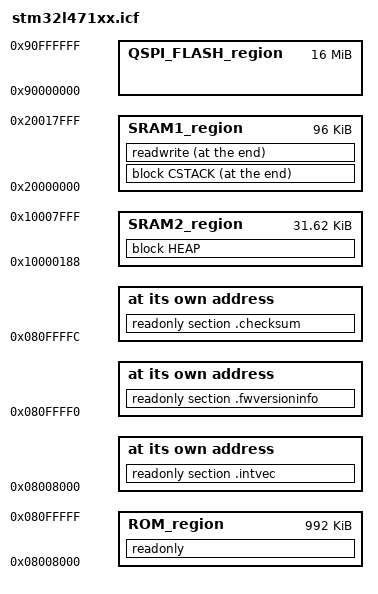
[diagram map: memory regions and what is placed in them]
/* *** IAR (icf)linker file for the firmware inside STM32L471RGT6 and STM32L471VGT6 *** */
//
//    	CSTACK:  4kByte 
//      HEAP:   68kByte 
//		
//
//              
//                     SRAM1 description (96kByte)
//      0x20017FFF      -------------------------       CSTACK start      
//      SRAM1 end       |                   |   |
//                      |       CSTACK      |   |
//                      |       grows       |   |       
//                      |       down        |   |		4kByte (min. 2kByte for Micropython)
//						|                   |   |
//      0x20017000      |                   v   |		CSTACK end
//                      |-----------------------|                
//      0x20016FFF      |                       |      
//                      |                       |
//                      |                       |
//                      |                       |      
//                      |                       |
//                      |                       |		
//                      |                       |
//                      |                       |
//                      |                       |
//                      |                       |
//                      |                       |
//                      |        BSS segment    |		92kkByte 
//                      |                       |
// 						|        Data segment   |
//                      |                       |
// 						|                       |
//                      |                       |
//						|                       |
//                      |                       |
//					 	|                       |
//                      |                       |
//      0x20000000      |-----------------------|         
//      SRAM1 start
//                      
//	
//	
//
//
//                      SRAM2 description (32kByte)
//      0x10007FFF      -------------------------            
//      SRAM2 end       |                   ^  	|                  
//          			|                   |  	|
//                      |                	|   |
//                      |       HEAP        |   |		32kByte-392Byte
//                      |       grows 		|   |		(min. 16kByte for Micropython) 
//                      |       up          |   |
// 						|       			|   |
//                      |       			|   |		
//                      |       			|   |
//                      |       			|   |      	
//                      |       			|   |             
//                      |       			|   |
//                      |       			|   |
//                      |       			|   |
//                		|       			|   |
//		0x10000188		|       			|   |
//                      |-----------------------|
//      0x10000187      |          				|                      
//						|Interrupt Vector Table |	     392Byte reserved to copy IVT
//						|                       |
//      0x10000000    	-------------------------
//      SRAM2 start
//
//
//
//
//                      ROM description (internal flash memory 1MByte)
//      0x080FFFFF      -------------------------            
//      ROM end       	|CRC32, firmware version|                  
//                      |                      	|
//                      |                		|
//                      |                   	|      	
//                      |                  		|
//                      |                      	|
//                      |                      	|
//                      |                      	|
//                      |						|                
//                      |                       | 
//                      |            			|
//                      | mbed +                |		
//                      | Micropython +         |		992kByte-392Byte
//                      | and more      	    |      
//                      |                       |
//                      |                       |
//                      |                       |
//                      |                       |
//                      |                       |
//                      |                       |
//                      |                  	    |       
//                      |                       |
//                      |                       |
//                      |                       |
//                      |                       |
//                      |                       |
//      0x08008188      |                       |
//                      |-----------------------|
//      0x08008187      |                       |  
//                      |Interrupt Vector Table |	     392Byte	
//      0x08008000      |                       |
//                      |---------------------- |
//      0x08007FFF      |CRC32                  |
//                      |						|
//                      |                       |
//                      | Bootloader OpenBlt    |		 32kByte
//                      |                       |
//                      |                       |
//      0x08000000      -------------------------
//      ROM start
//
//
//
//               	  QuadSPI-NOR-Flash description
//                    (MT25QU128ABA with a size of 16MByte)                 			 
//      0x90FFFFFF      -------------------------            
//      QuadSPI end     |						|                  
//                      |                      	|
//                      |                		|
//                      |                   	|      	
//                      |                  		|
//                      |                      	|
//                      |                      	|
//                      |                      	|
//                      |						|                
//                      |                       | 
//                      |            			|
//                      |                       |		
//                      | Flash File System     |
//                      |       			    |      
//                      |                       |
//                      |                       |
//                      |                       |
//                      |                       |
//                      |                       |
//                      |                       |
//                      |                  	    |       
//                      |                       |
//                      |                       |
//                      |                       |
//                      |                       |
//                      |                       |
//                      |                       |
//                      |                       |
//                      |                       |
//                      |						|
//                      |                       |
//                      |                       |	
//                      |                       |
//                      |                       |
//      0x90000000      -------------------------
//      QuadSPI start
//
//
/* **************************************************************** */

/* [ROM = 1024kb = 0x100000] */
/* Interrupt Vector Table */
/* Bootloader space of 32kByte reserved */  
define symbol __intvec_start__     = 0x08008000;

define symbol __region_ROM_start__ = 0x08008000;
define symbol __region_ROM_end__   = 0x080FFFFF;


/* [RAM = 96kb + 32kb = 0x20000] */
/* Vector table dynamic copy: Total: 98 vectors = 392 bytes (0x188) to be reserved in RAM */
define symbol __NVIC_start__          = 0x10000000;
define symbol __NVIC_end__            = 0x10000187; /* Aligned on 8 bytes (392 = 49 x 8) */
define symbol __region_SRAM2_start__  = 0x10000188;
define symbol __region_SRAM2_end__    = 0x10007FFF;
define symbol __region_SRAM1_start__  = 0x20000000;
define symbol __region_SRAM1_end__    = 0x20017FFF;
define symbol __region_RAM_end__      = __region_SRAM1_end__; 
export symbol __region_RAM_end__;	  /* used for micropython gc_collect_root */	

/* [QSPI_FLASH = 16MByte = 0x1000000] */
define symbol __region_QSPI_FLASH_start__    = 0x90000000;
define symbol __region_QSPI_FLASH_end__      = 0x90FFFFFF;


/* Memory regions */
define memory mem with size = 4G;
define region ROM_region = mem:[from __region_ROM_start__ to __region_ROM_end__];
define region SRAM1_region = mem:[from __region_SRAM1_start__ to __region_SRAM1_end__];
define region SRAM2_region = mem:[from __region_SRAM2_start__ to __region_SRAM2_end__];
define region QSPI_FLASH_region = mem:[from __region_QSPI_FLASH_start__ to __region_QSPI_FLASH_end__];


/* Stack and Heap */
/* CSTACK:  4kByte = 0x1000 */
/* HEAP:  32kByte = 0x8000 */
define symbol __size_cstack__ = 0x1000;
define symbol __size_heap__   = 0x7e78;  
define block CSTACK    with alignment = 8, size = __size_cstack__   { };
define block HEAP      with alignment = 8, size = __size_heap__     { };
// define block HEAPSTACK with fixed order { block HEAP, block CSTACK };


/* handle initialization */
/* initialize rw sections during copy from ROM to RAM, also move the interrupt vector table to address 0x08000000 */
initialize by copy with packing = zeros { readwrite };
do not initialize  { section .noinit };										/* do not initialise zero-init data */

place at address mem:__intvec_start__ { readonly section .intvec };			/* place startup code at address 0x08000000 */
place at address mem: 0x080FFFF0 {readonly section .fwversioninfo};     	/* place the firmware version string in front of the checksum */
place at address mem: 0x080FFFFC {readonly section .checksum};        		/* place the four byte long checksum at the end of the internal flash */
place in ROM_region   { readonly };											/* place constants, initializers and code in ROM: .rodata, .data_init, .text */
place at end of SRAM1_region {block CSTACK, readwrite};								/* place heap and stack at the end of SRAM1 */
//place at start of SRAM1_region {readwrite};									/* place .data, .bss, and .noinit, (readwrite) normally here */
place in SRAM2_region {block HEAP};									/* place .data, .bss, and .noinit, (readwrite) normally here */
//place in SRAM2_region { };													/* reserved */
place in QSPI_FLASH_region { };

